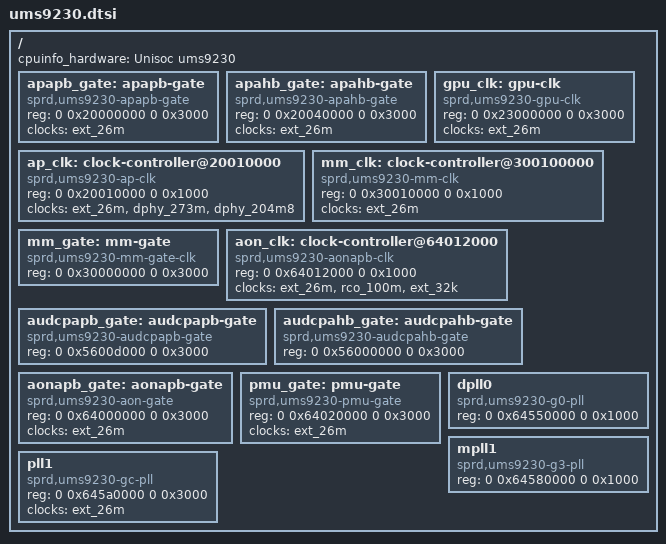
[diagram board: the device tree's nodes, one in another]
/*
 * Spreadtrum ums512 board DTS file
 *
 * Copyright (C) 2019, Spreadtrum Communications Inc.
 *
 * This file is licensed under a dual GPLv2 or X11 license.
 */

#include "qogirl6.dtsi"

/ {
	cpuinfo_hardware = "Unisoc ums9230";

	apapb_gate: apapb-gate {
		compatible = "sprd,ums9230-apapb-gate";
		/*sprd,syscon = <&ap_apb_regs>;*/ /* 0x20000000 */
		reg = <0 0x20000000 0 0x3000>;
		clocks = <&ext_26m>;
		clock-names = "ext-26m";
		#clock-cells = <1>;
	};

	apahb_gate: apahb-gate {
		compatible = "sprd,ums9230-apahb-gate";
		/*sprd,syscon = <&ap_ahb_regs>;*/ /* 0x20400000 */
		reg = <0 0x20040000 0 0x3000>;
		clocks = <&ext_26m>;
		clock-names = "ext-26m";
		#clock-cells = <1>;
	};

	ap_clk: clock-controller@20010000 {
		compatible = "sprd,ums9230-ap-clk";
		reg = <0 0x20010000 0 0x1000>;
		clocks = <&ext_26m>, <&dphy_273m>, <&dphy_204m8>;
		clock-names = "ext-26m", "dphy-273m", "dphy-204m8";
		#clock-cells = <1>;
	};

	gpu_clk: gpu-clk {
		compatible = "sprd,ums9230-gpu-clk";
		/*sprd,syscon = <&gpu_apb_regs>;*/ /* 0x23000000 */
		reg = <0 0x23000000 0 0x3000>;
		clocks = <&ext_26m>;
		clock-names = "ext-26m";
		#clock-cells = <1>;
	 };

	mm_clk: clock-controller@300100000 {
		compatible = "sprd,ums9230-mm-clk";
		reg = <0 0x30010000 0 0x1000>;
		clocks = <&ext_26m>;
		clock-names = "ext-26m";
		#clock-cells = <1>;
	};

	mm_gate: mm-gate {
		compatible = "sprd,ums9230-mm-gate-clk";
		/*sprd,syscon = <&mm_ahb_regs>;*/ /* 0x30000000 */
		reg = <0 0x30000000 0 0x3000>;
		#clock-cells = <1>;
	};

	aon_clk: clock-controller@64012000 {
		compatible = "sprd,ums9230-aonapb-clk";
		reg = <0 0x64012000 0 0x1000>;
		clocks = <&ext_26m>, <&rco_100m>, <&ext_32k>;
		clock-names = "ext-26m", "rco-100m", "ext-32k";
		#clock-cells = <1>;
	};

	audcpapb_gate: audcpapb-gate {
		compatible = "sprd,ums9230-audcpapb-gate";
		/*sprd,syscon = <&audcp_apb_regs>;*/ /* 0x5600d000 */
		reg = <0 0x5600d000 0 0x3000>;
		#clock-cells = <1>;
	};

	audcpahb_gate: audcpahb-gate {
		compatible = "sprd,ums9230-audcpahb-gate";
		/*sprd,syscon = <&audcp_ahb_regs>;*/ /* 0x56000000 */
		reg = <0 0x56000000 0 0x3000>;
		#clock-cells = <1>;
	};

	aonapb_gate: aonapb-gate {
		compatible = "sprd,ums9230-aon-gate";
		/*sprd,syscon = <&aon_apb_regs>;*/ /* 0x64000000 */
		reg = <0 0x64000000 0 0x3000>;
		clocks = <&ext_26m>;
		clock-names = "ext-26m";
		#clock-cells = <1>;
	};

	pmu_gate: pmu-gate {
		compatible = "sprd,ums9230-pmu-gate";
		/*sprd,syscon = <&pmu_apb_regs>;*/ /* 0x64020000 */
		reg = <0 0x64020000 0 0x3000>;
		clocks = <&ext_26m>;
		clock-names = "ext-26m";
		#clock-cells = <1>;
	};

	dpll0: dpll0 {
		compatible = "sprd,ums9230-g0-pll";
		/*sprd,syscon = <&anlg_phy_g0_regs>;*/ /* 0x64550000 */
		reg = <0 0x64550000 0 0x1000>;
		#clock-cells = <1>;
       };

	mpll1: mpll1 {
		compatible = "sprd,ums9230-g3-pll";
		/*sprd,syscon = <&anlg_phy_g3_regs>;*/ /* 0x64580000 */
		reg = <0 0x64580000 0 0x1000>;
		#clock-cells = <1>;
       };

	pll1: pll1 {
		compatible = "sprd,ums9230-gc-pll";
		/*sprd,syscon = <&anlg_phy_gc_regs>;*/ /* 0x645a0000 */
		reg = <0 0x645a0000 0 0x3000>;
		clocks = <&ext_26m>;
		clock-names = "ext-26m";
		#clock-cells = <1>;
      };
};
